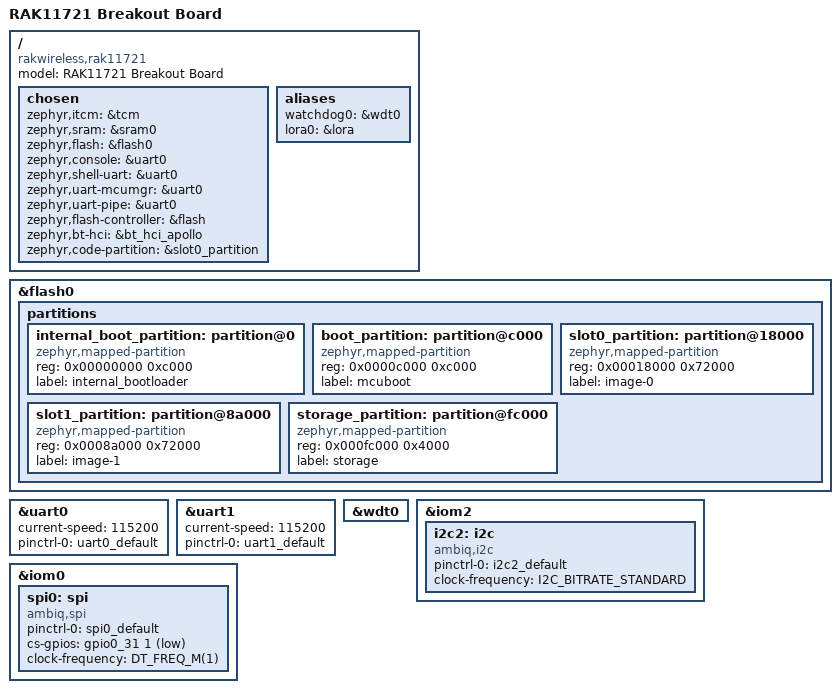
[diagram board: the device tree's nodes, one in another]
/*
 * SPDX-FileCopyrightText: Copyright (c) 2026 RAKwireless Technology Limited
 * SPDX-License-Identifier: Apache-2.0
 */

/dts-v1/;
#include <rakwireless/rak11720.dtsi>
#include "rak11721-pinctrl.dtsi"

/ {
	compatible = "rakwireless,rak11721";
	model = "RAK11721 Breakout Board";

	chosen {
		zephyr,itcm = &tcm;
		zephyr,sram = &sram0;
		zephyr,flash = &flash0;
		zephyr,console = &uart0;
		zephyr,shell-uart = &uart0;
		zephyr,uart-mcumgr = &uart0;
		zephyr,uart-pipe = &uart0;
		zephyr,flash-controller = &flash;
		zephyr,bt-hci = &bt_hci_apollo;
		zephyr,code-partition = &slot0_partition;
	};

	aliases {
		watchdog0 = &wdt0;
		lora0 = &lora;
	};
};

&flash0 {
	partitions {
		ranges;
		#address-cells = <1>;
		#size-cells = <1>;

		internal_boot_partition: partition@0 {
			compatible = "zephyr,mapped-partition";
			reg = <0x00000000 0xc000>;
			label = "internal_bootloader";
		};

		boot_partition: partition@c000 {
			compatible = "zephyr,mapped-partition";
			reg = <0x0000c000 0xc000>;
			label = "mcuboot";
		};

		slot0_partition: partition@18000 {
			compatible = "zephyr,mapped-partition";
			reg = <0x00018000 0x72000>;
			label = "image-0";
		};

		slot1_partition: partition@8a000 {
			compatible = "zephyr,mapped-partition";
			reg = <0x0008a000 0x72000>;
			label = "image-1";
		};

		storage_partition: partition@fc000 {
			compatible = "zephyr,mapped-partition";
			reg = <0x000fc000 0x4000>;
			label = "storage";
		};
	};
};

&uart0 {
	current-speed = <115200>;
	pinctrl-0 = <&uart0_default>;
	pinctrl-names = "default";
	status = "okay";
};

&uart1 {
	current-speed = <115200>;
	pinctrl-0 = <&uart1_default>;
	pinctrl-names = "default";
	status = "okay";
};

&wdt0 {
	status = "okay";
};

&iom2 {
	i2c2: i2c {
		compatible = "ambiq,i2c";
		pinctrl-0 = <&i2c2_default>;
		pinctrl-names = "default";
		clock-frequency = <I2C_BITRATE_STANDARD>;
		status = "okay";
	};
};

&iom0 {
	spi0: spi {
		compatible = "ambiq,spi";
		pinctrl-0 = <&spi0_default>;
		pinctrl-names = "default";
		cs-gpios = <&gpio0_31 1 GPIO_ACTIVE_LOW>;
		clock-frequency = <DT_FREQ_M(1)>;
		status = "okay";
	};
};
